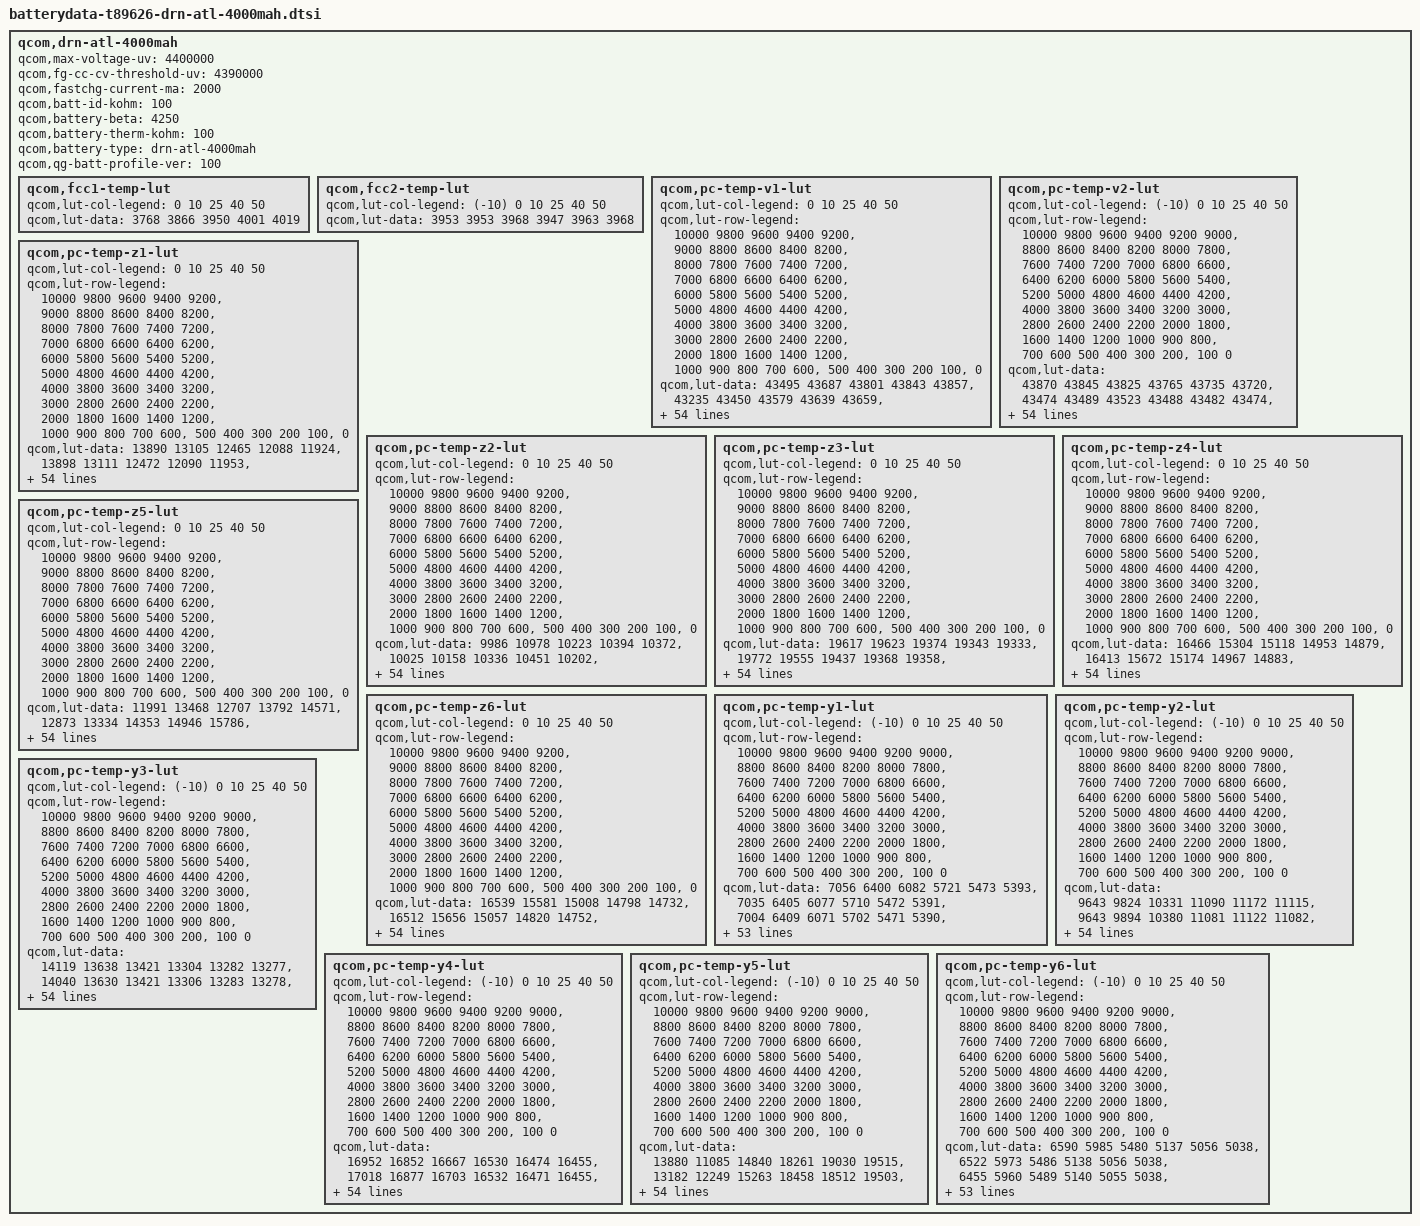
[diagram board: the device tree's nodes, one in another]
qcom,drn-atl-4000mah {
    /* 3818385_Wingtech_T89626AA1_DRN_4000mAH_FG_averaged_MasterSlave_Jan16th2019 */
    qcom,max-voltage-uv = <4400000>;
    qcom,fg-cc-cv-threshold-uv = <4390000>;
    qcom,fastchg-current-ma = <2000>;
    qcom,batt-id-kohm = <100>;
    qcom,battery-beta = <4250>;
    qcom,battery-therm-kohm = <100>;
    qcom,battery-type = "drn-atl-4000mah";
    qcom,qg-batt-profile-ver = <100>;

	qcom,fcc1-temp-lut {
		qcom,lut-col-legend = <0 10 25 40 50>;
		qcom,lut-data = <3768 3866 3950 4001 4019>;
	};

	qcom,fcc2-temp-lut {
		qcom,lut-col-legend = <(-10) 0 10 25 40 50>;
		qcom,lut-data = <3953 3953 3968 3947 3963 3968>;
	};

	qcom,pc-temp-v1-lut {
		qcom,lut-col-legend = <0 10 25 40 50>;
		qcom,lut-row-legend = <10000 9800 9600 9400 9200>,
			<9000 8800 8600 8400 8200>,
			<8000 7800 7600 7400 7200>,
			<7000 6800 6600 6400 6200>,
			<6000 5800 5600 5400 5200>,
			<5000 4800 4600 4400 4200>,
			<4000 3800 3600 3400 3200>,
			<3000 2800 2600 2400 2200>,
			<2000 1800 1600 1400 1200>,
			<1000 900 800 700 600>,
			<500 400 300 200 100>,
			<0>;
		qcom,lut-data = <43495 43687 43801 43843 43857>,
			<43235 43450 43579 43639 43659>,
			<42985 43208 43352 43423 43445>,
			<42747 42966 43120 43201 43225>,
			<42519 42728 42885 42972 42999>,
			<42296 42493 42651 42740 42769>,
			<42076 42263 42416 42508 42537>,
			<41860 42039 42184 42274 42304>,
			<41649 41819 41956 42043 42073>,
			<41442 41603 41731 41813 41845>,
			<41240 41389 41510 41587 41618>,
			<41050 41181 41293 41366 41396>,
			<40867 40991 41083 41149 41176>,
			<40667 40813 40886 40938 40963>,
			<40420 40617 40694 40732 40754>,
			<40169 40379 40500 40534 40553>,
			<39982 40144 40300 40343 40361>,
			<39840 39972 40109 40161 40177>,
			<39711 39838 39945 39986 39998>,
			<39580 39704 39791 39825 39833>,
			<39452 39561 39604 39647 39657>,
			<39328 39411 39354 39402 39429>,
			<39206 39233 39112 39136 39172>,
			<39087 39006 38929 38953 38981>,
			<38973 38803 38774 38823 38845>,
			<38862 38666 38663 38712 38729>,
			<38757 38558 38583 38609 38618>,
			<38653 38477 38515 38516 38517>,
			<38555 38416 38446 38428 38423>,
			<38473 38367 38380 38344 38333>,
			<38409 38324 38318 38268 38252>,
			<38355 38289 38257 38198 38179>,
			<38310 38256 38202 38136 38112>,
			<38272 38227 38151 38078 38049>,
			<38236 38201 38105 38026 37992>,
			<38198 38169 38060 37975 37934>,
			<38159 38134 38019 37925 37871>,
			<38112 38090 37974 37871 37805>,
			<38052 38019 37906 37800 37726>,
			<37979 37920 37809 37706 37634>,
			<37882 37813 37702 37601 37530>,
			<37752 37692 37585 37487 37416>,
			<37607 37553 37453 37358 37286>,
			<37448 37389 37293 37197 37129>,
			<37326 37254 37155 37062 36998>,
			<37232 37162 37064 36976 36916>,
			<37195 37133 37042 36952 36895>,
			<37165 37108 37024 36936 36877>,
			<37138 37080 37002 36912 36853>,
			<37066 37018 36935 36836 36769>,
			<36819 36754 36657 36539 36453>,
			<36368 36309 36215 36093 36007>,
			<35792 35734 35639 35514 35426>,
			<35015 34950 34856 34723 34632>,
			<33775 33715 33613 33488 33393>,
			<30000 30000 30000 30000 30000>;
	};

	qcom,pc-temp-v2-lut {
		qcom,lut-col-legend = <(-10) 0 10 25 40 50>;
		qcom,lut-row-legend = <10000 9800 9600 9400 9200 9000>,
			<8800 8600 8400 8200 8000 7800>,
			<7600 7400 7200 7000 6800 6600>,
			<6400 6200 6000 5800 5600 5400>,
			<5200 5000 4800 4600 4400 4200>,
			<4000 3800 3600 3400 3200 3000>,
			<2800 2600 2400 2200 2000 1800>,
			<1600 1400 1200 1000 900 800>,
			<700 600 500 400 300 200>,
			<100 0>;
		qcom,lut-data = <43870 43845 43825 43765 43735 43720>,
			<43474 43489 43523 43488 43482 43474>,
			<43114 43162 43237 43224 43236 43233>,
			<42791 42871 42969 42973 42996 42997>,
			<42496 42611 42719 42735 42764 42766>,
			<42243 42364 42476 42503 42533 42537>,
			<42049 42123 42229 42270 42301 42305>,
			<41877 41887 41987 42039 42070 42074>,
			<41657 41641 41759 41812 41843 41847>,
			<41357 41369 41545 41588 41617 41621>,
			<41101 41144 41334 41368 41395 41399>,
			<40971 41020 41117 41152 41179 41180>,
			<40874 40926 40902 40939 40966 40965>,
			<40684 40766 40703 40734 40760 40758>,
			<40218 40453 40524 40531 40557 40557>,
			<39763 40118 40334 40336 40361 40363>,
			<39540 39872 40107 40155 40174 40176>,
			<39381 39655 39857 39983 39996 39996>,
			<39218 39452 39625 39797 39816 39816>,
			<39043 39257 39408 39590 39638 39642>,
			<38876 39073 39205 39377 39453 39460>,
			<38719 38897 39016 39163 39232 39237>,
			<38570 38730 38842 38948 38992 38996>,
			<38446 38571 38686 38772 38805 38810>,
			<38343 38412 38546 38635 38665 38672>,
			<38255 38275 38418 38517 38546 38553>,
			<38179 38187 38291 38406 38437 38442>,
			<38113 38122 38171 38304 38338 38339>,
			<38052 38064 38077 38211 38247 38246>,
			<37995 38012 38002 38127 38162 38161>,
			<37940 37963 37941 38050 38085 38083>,
			<37885 37917 37893 37978 38013 38011>,
			<37831 37873 37855 37909 37948 37946>,
			<37774 37828 37816 37846 37878 37874>,
			<37715 37782 37778 37790 37800 37790>,
			<37654 37734 37737 37736 37718 37697>,
			<37590 37681 37691 37674 37627 37595>,
			<37523 37624 37641 37605 37529 37481>,
			<37454 37560 37579 37531 37438 37380>,
			<37387 37489 37499 37455 37361 37299>,
			<37319 37407 37404 37372 37284 37220>,
			<37253 37306 37301 37273 37187 37122>,
			<37187 37181 37185 37152 37070 37008>,
			<37116 37067 37046 37022 36943 36886>,
			<37036 36966 36912 36896 36836 36788>,
			<36936 36884 36831 36841 36794 36748>,
			<36883 36848 36804 36822 36780 36732>,
			<36812 36812 36773 36797 36759 36714>,
			<36723 36761 36728 36755 36721 36673>,
			<36574 36645 36628 36643 36586 36520>,
			<36322 36378 36358 36344 36230 36147>,
			<35914 35938 35895 35869 35724 35636>,
			<35323 35329 35262 35231 35069 34969>,
			<34461 34475 34383 34371 34169 34061>,
			<33112 33145 33039 32963 32816 32714>,
			<28445 28081 27842 28239 27825 27854>;
	};

	qcom,pc-temp-z1-lut {
		qcom,lut-col-legend = <0 10 25 40 50>;
		qcom,lut-row-legend = <10000 9800 9600 9400 9200>,
			<9000 8800 8600 8400 8200>,
			<8000 7800 7600 7400 7200>,
			<7000 6800 6600 6400 6200>,
			<6000 5800 5600 5400 5200>,
			<5000 4800 4600 4400 4200>,
			<4000 3800 3600 3400 3200>,
			<3000 2800 2600 2400 2200>,
			<2000 1800 1600 1400 1200>,
			<1000 900 800 700 600>,
			<500 400 300 200 100>,
			<0>;
		qcom,lut-data = <13890 13105 12465 12088 11924>,
			<13898 13111 12472 12090 11953>,
			<13902 13112 12474 12087 11956>,
			<13901 13106 12465 12083 11955>,
			<13899 13097 12449 12075 11952>,
			<13899 13082 12438 12067 11948>,
			<13893 13070 12430 12059 11946>,
			<13879 13058 12422 12053 11943>,
			<13874 13046 12412 12049 11943>,
			<13878 13045 12402 12047 11944>,
			<13879 13044 12397 12046 11945>,
			<13857 13040 12395 12046 11945>,
			<13808 13018 12392 12046 11945>,
			<13774 12977 12387 12046 11945>,
			<13747 12961 12382 12045 11944>,
			<13720 12964 12380 12044 11944>,
			<13709 12968 12380 12045 11945>,
			<13699 12970 12380 12046 11946>,
			<13692 12970 12384 12047 11947>,
			<13682 12971 12390 12047 11947>,
			<13663 12986 12392 12047 11948>,
			<13654 13009 12392 12047 11948>,
			<13667 13016 12391 12049 11948>,
			<13684 13017 12394 12051 11949>,
			<13694 13016 12402 12053 11951>,
			<13706 13012 12407 12055 11953>,
			<13714 13007 12411 12059 11956>,
			<13706 13005 12415 12063 11960>,
			<13690 13006 12421 12067 11964>,
			<13684 13010 12431 12072 11968>,
			<13707 13018 12437 12076 11972>,
			<13734 13039 12439 12082 11976>,
			<13736 13051 12441 12087 11980>,
			<13725 13053 12446 12092 11983>,
			<13717 13053 12458 12097 11987>,
			<13726 13059 12465 12102 11991>,
			<13744 13076 12467 12105 11994>,
			<13753 13088 12470 12109 11997>,
			<13749 13085 12476 12114 12000>,
			<13745 13080 12488 12120 12005>,
			<13765 13082 12497 12126 12009>,
			<13827 13109 12501 12131 12013>,
			<13838 13126 12505 12136 12016>,
			<13817 13124 12511 12142 12019>,
			<13817 13120 12525 12150 12024>,
			<13790 13112 12541 12154 12027>,
			<13806 13122 12531 12156 12027>,
			<13811 13106 12536 12161 12030>,
			<13812 13120 12532 12166 12035>,
			<13836 13143 12546 12170 12039>,
			<13842 13126 12546 12181 12047>,
			<13816 13166 12547 12186 12055>,
			<13829 13180 12568 12197 12065>,
			<13860 13219 12612 12217 12078>,
			<13860 13219 12612 12217 12078>,
			<13860 13219 12612 12217 12078>;
	};

	qcom,pc-temp-z2-lut {
		qcom,lut-col-legend = <0 10 25 40 50>;
		qcom,lut-row-legend = <10000 9800 9600 9400 9200>,
			<9000 8800 8600 8400 8200>,
			<8000 7800 7600 7400 7200>,
			<7000 6800 6600 6400 6200>,
			<6000 5800 5600 5400 5200>,
			<5000 4800 4600 4400 4200>,
			<4000 3800 3600 3400 3200>,
			<3000 2800 2600 2400 2200>,
			<2000 1800 1600 1400 1200>,
			<1000 900 800 700 600>,
			<500 400 300 200 100>,
			<0>;
		qcom,lut-data = <9986 10978 10223 10394 10372>,
			<10025 10158 10336 10451 10202>,
			<10062 10152 10386 10493 10362>,
			<10100 10150 10377 10498 10446>,
			<10141 10141 10355 10480 10462>,
			<10159 10116 10332 10454 10466>,
			<10159 10093 10302 10420 10455>,
			<10158 10079 10277 10380 10425>,
			<10156 10067 10255 10358 10390>,
			<10150 10056 10239 10345 10337>,
			<10143 10045 10236 10336 10283>,
			<10130 10038 10244 10327 10252>,
			<10110 10053 10255 10313 10230>,
			<10086 10105 10404 10301 10233>,
			<10048 10131 10613 10289 10244>,
			<10012 10103 10655 10281 10257>,
			<10005 10068 10650 10282 10271>,
			<10007 10072 10636 10293 10285>,
			<10008 10102 10531 10299 10300>,
			<10005 10128 10376 10303 10323>,
			<9997 10143 10346 10311 10343>,
			<9990 10154 10375 10346 10347>,
			<9979 10163 10396 10391 10342>,
			<9968 10172 10386 10388 10340>,
			<9966 10176 10360 10335 10358>,
			<9968 10175 10345 10306 10376>,
			<9970 10172 10346 10347 10390>,
			<9975 10172 10354 10424 10410>,
			<9984 10183 10369 10459 10402>,
			<9993 10196 10394 10474 10337>,
			<10001 10200 10405 10475 10275>,
			<10009 10202 10409 10456 10250>,
			<10017 10204 10412 10428 10231>,
			<10025 10209 10415 10421 10230>,
			<10033 10215 10418 10419 10260>,
			<10045 10220 10422 10423 10300>,
			<10058 10226 10430 10445 10343>,
			<10073 10233 10441 10480 10390>,
			<10090 10244 10456 10510 10427>,
			<10108 10257 10481 10550 10459>,
			<10119 10266 10500 10571 10478>,
			<10128 10270 10514 10556 10476>,
			<10147 10275 10520 10534 10470>,
			<10182 10283 10508 10509 10457>,
			<10280 10408 10544 10508 10462>,
			<10163 10447 10566 10527 10462>,
			<10620 10489 10541 10502 10470>,
			<12381 10555 10535 10524 10463>,
			<14367 10597 10521 10524 10500>,
			<15164 10649 10579 10627 10671>,
			<11677 10631 10687 10622 10375>,
			<10005 10560 10698 10469 10270>,
			<9961 10482 10664 10416 10218>,
			<9793 10361 10621 10333 10175>,
			<9793 10361 10621 10333 10175>,
			<9793 10361 10621 10333 10175>;
	};

	qcom,pc-temp-z3-lut {
		qcom,lut-col-legend = <0 10 25 40 50>;
		qcom,lut-row-legend = <10000 9800 9600 9400 9200>,
			<9000 8800 8600 8400 8200>,
			<8000 7800 7600 7400 7200>,
			<7000 6800 6600 6400 6200>,
			<6000 5800 5600 5400 5200>,
			<5000 4800 4600 4400 4200>,
			<4000 3800 3600 3400 3200>,
			<3000 2800 2600 2400 2200>,
			<2000 1800 1600 1400 1200>,
			<1000 900 800 700 600>,
			<500 400 300 200 100>,
			<0>;
		qcom,lut-data = <19617 19623 19374 19343 19333>,
			<19772 19555 19437 19368 19358>,
			<19859 19599 19475 19395 19372>,
			<19853 19661 19495 19409 19381>,
			<19818 19684 19507 19417 19391>,
			<19784 19695 19511 19422 19399>,
			<19749 19699 19513 19423 19402>,
			<19716 19694 19513 19423 19402>,
			<19707 19682 19511 19423 19402>,
			<19706 19676 19506 19418 19396>,
			<19706 19675 19499 19412 19387>,
			<19706 19673 19486 19404 19381>,
			<19705 19665 19475 19394 19375>,
			<19705 19649 19475 19389 19371>,
			<19740 19638 19478 19386 19367>,
			<19788 19629 19476 19382 19362>,
			<19794 19617 19469 19376 19357>,
			<19768 19600 19460 19370 19352>,
			<19744 19573 19449 19366 19349>,
			<19744 19559 19437 19364 19346>,
			<19751 19561 19436 19363 19344>,
			<19758 19568 19449 19369 19346>,
			<19771 19576 19460 19379 19349>,
			<19785 19593 19458 19379 19348>,
			<19789 19604 19451 19367 19338>,
			<19791 19603 19445 19358 19330>,
			<19791 19600 19438 19358 19334>,
			<19791 19597 19434 19363 19346>,
			<19790 19594 19435 19369 19355>,
			<19789 19590 19439 19383 19367>,
			<19781 19586 19444 19394 19375>,
			<19768 19582 19453 19397 19374>,
			<19755 19577 19459 19397 19370>,
			<19740 19570 19459 19394 19366>,
			<19725 19563 19455 19386 19358>,
			<19713 19558 19450 19379 19352>,
			<19703 19553 19446 19375 19352>,
			<19691 19550 19441 19371 19351>,
			<19675 19548 19437 19368 19350>,
			<19661 19547 19434 19366 19348>,
			<19653 19544 19432 19364 19346>,
			<19648 19539 19429 19362 19347>,
			<19642 19532 19427 19360 19348>,
			<19633 19524 19420 19359 19348>,
			<19403 19481 19406 19353 19343>,
			<19279 19454 19401 19349 19338>,
			<19283 19432 19392 19348 19329>,
			<19283 19410 19377 19340 19328>,
			<19258 19398 19366 19339 19323>,
			<19257 19384 19360 19330 19312>,
			<19261 19399 19355 19333 19347>,
			<19271 19360 19341 19346 19350>,
			<19313 19352 19340 19347 19351>,
			<19315 19346 19332 19353 19354>,
			<19315 19346 19332 19353 19354>,
			<19315 19346 19332 19353 19354>;
	};

	qcom,pc-temp-z4-lut {
		qcom,lut-col-legend = <0 10 25 40 50>;
		qcom,lut-row-legend = <10000 9800 9600 9400 9200>,
			<9000 8800 8600 8400 8200>,
			<8000 7800 7600 7400 7200>,
			<7000 6800 6600 6400 6200>,
			<6000 5800 5600 5400 5200>,
			<5000 4800 4600 4400 4200>,
			<4000 3800 3600 3400 3200>,
			<3000 2800 2600 2400 2200>,
			<2000 1800 1600 1400 1200>,
			<1000 900 800 700 600>,
			<500 400 300 200 100>,
			<0>;
		qcom,lut-data = <16466 15304 15118 14953 14879>,
			<16413 15672 15174 14967 14883>,
			<16332 15578 15187 14960 14885>,
			<16213 15419 15131 14945 14882>,
			<16044 15293 15034 14905 14858>,
			<15891 15179 14967 14864 14825>,
			<15775 15086 14915 14834 14799>,
			<15672 15020 14871 14808 14777>,
			<15579 14966 14835 14783 14759>,
			<15494 14921 14803 14759 14743>,
			<15415 14882 14781 14743 14732>,
			<15340 14847 14765 14735 14725>,
			<15270 14808 14749 14729 14718>,
			<15205 14766 14721 14721 14711>,
			<15139 14747 14693 14711 14702>,
			<15078 14753 14686 14702 14695>,
			<15038 14763 14685 14695 14688>,
			<15012 14761 14684 14690 14681>,
			<14986 14754 14683 14685 14676>,
			<14948 14745 14685 14679 14673>,
			<14901 14733 14695 14677 14671>,
			<14863 14722 14746 14721 14705>,
			<14831 14726 14804 14799 14784>,
			<14805 14779 14839 14828 14817>,
			<14792 14828 14868 14839 14826>,
			<14784 14843 14874 14843 14829>,
			<14780 14852 14861 14833 14819>,
			<14781 14853 14840 14812 14791>,
			<14784 14839 14820 14788 14764>,
			<14786 14819 14797 14757 14736>,
			<14784 14802 14775 14731 14712>,
			<14782 14785 14751 14712 14698>,
			<14779 14770 14733 14698 14687>,
			<14775 14755 14724 14695 14684>,
			<14771 14741 14718 14695 14684>,
			<14765 14729 14715 14695 14684>,
			<14757 14718 14714 14697 14687>,
			<14752 14712 14713 14701 14693>,
			<14748 14714 14716 14707 14699>,
			<14745 14717 14726 14718 14708>,
			<14743 14718 14731 14724 14713>,
			<14742 14715 14721 14716 14706>,
			<14736 14712 14712 14708 14697>,
			<14724 14711 14711 14711 14701>,
			<14874 14699 14693 14701 14694>,
			<14994 14700 14675 14679 14675>,
			<14984 14713 14668 14667 14670>,
			<14976 14728 14670 14653 14650>,
			<14992 14735 14669 14638 14636>,
			<14983 14745 14674 14653 14650>,
			<14984 14741 14707 14681 14651>,
			<14999 14801 14730 14672 14651>,
			<14976 14821 14734 14673 14654>,
			<14991 14839 14749 14671 14653>,
			<14991 14839 14749 14671 14653>,
			<14991 14839 14749 14671 14653>;
	};

	qcom,pc-temp-z5-lut {
		qcom,lut-col-legend = <0 10 25 40 50>;
		qcom,lut-row-legend = <10000 9800 9600 9400 9200>,
			<9000 8800 8600 8400 8200>,
			<8000 7800 7600 7400 7200>,
			<7000 6800 6600 6400 6200>,
			<6000 5800 5600 5400 5200>,
			<5000 4800 4600 4400 4200>,
			<4000 3800 3600 3400 3200>,
			<3000 2800 2600 2400 2200>,
			<2000 1800 1600 1400 1200>,
			<1000 900 800 700 600>,
			<500 400 300 200 100>,
			<0>;
		qcom,lut-data = <11991 13468 12707 13792 14571>,
			<12873 13334 14353 14946 15786>,
			<13396 13888 15503 16213 16665>,
			<13424 14831 16164 16884 17319>,
			<13398 15555 16671 17226 17967>,
			<13386 16206 17239 17543 18613>,
			<13392 16729 17828 17925 19152>,
			<13406 17034 18428 18331 19645>,
			<13458 17283 19168 18833 20042>,
			<13605 17714 19960 19582 20212>,
			<13747 18719 20403 20033 20139>,
			<13788 19795 20657 19847 20017>,
			<13796 20642 20963 19506 20135>,
			<13866 21601 24059 19579 20376>,
			<14755 22125 28256 20465 20922>,
			<15913 23083 28845 21145 21337>,
			<16091 24052 28059 21236 21442>,
			<15693 23691 27362 21282 21880>,
			<15365 21871 26872 21513 22440>,
			<15674 20757 26764 22620 23599>,
			<16713 22655 29176 24258 24881>,
			<17959 27078 41207 28694 26151>,
			<19828 33497 50895 33800 27170>,
			<22221 46082 47651 33277 26202>,
			<24630 54930 38554 25960 21272>,
			<27220 53025 31937 20267 17156>,
			<29969 47563 27294 18922 16571>,
			<33446 43319 24367 18141 16711>,
			<37140 40429 23766 18301 17419>,
			<38387 38077 23668 20231 19181>,
			<37552 36306 24131 22739 21309>,
			<36027 34883 27543 26055 23539>,
			<34063 33791 32201 29773 25830>,
			<30999 32800 35838 31642 27160>,
			<28493 32080 39316 32817 27978>,
			<27382 32034 40673 33303 28497>,
			<26603 32498 40639 32658 28874>,
			<25779 33229 40327 31158 29185>,
			<24595 34984 39023 29272 28761>,
			<23667 37403 35514 26393 25267>,
			<23687 37804 32847 24136 22436>,
			<24338 34795 31813 23143 22305>,
			<25612 32372 30644 22367 22342>,
			<27598 30930 27451 21379 21616>,
			<15578 26808 27864 21270 20863>,
			<11370 21931 28900 21718 20796>,
			<11409 18245 25503 22576 19118>,
			<11403 15889 22025 21937 21237>,
			<11144 15182 18784 25009 23779>,
			<11173 14809 18156 19576 17398>,
			<11253 15722 16182 16083 21431>,
			<11297 13230 14126 17230 20727>,
			<11631 12714 13797 16766 19688>,
			<11513 12350 13126 17045 19104>,
			<11513 12350 13126 17045 19104>,
			<11513 12350 13126 17045 19104>;
	};

	qcom,pc-temp-z6-lut {
		qcom,lut-col-legend = <0 10 25 40 50>;
		qcom,lut-row-legend = <10000 9800 9600 9400 9200>,
			<9000 8800 8600 8400 8200>,
			<8000 7800 7600 7400 7200>,
			<7000 6800 6600 6400 6200>,
			<6000 5800 5600 5400 5200>,
			<5000 4800 4600 4400 4200>,
			<4000 3800 3600 3400 3200>,
			<3000 2800 2600 2400 2200>,
			<2000 1800 1600 1400 1200>,
			<1000 900 800 700 600>,
			<500 400 300 200 100>,
			<0>;
		qcom,lut-data = <16539 15581 15008 14798 14732>,
			<16512 15656 15057 14820 14752>,
			<16460 15613 15073 14828 14760>,
			<16375 15536 15051 14827 14762>,
			<16238 15469 15009 14812 14755>,
			<16113 15401 14978 14796 14746>,
			<16015 15341 14951 14783 14737>,
			<15929 15293 14926 14771 14729>,
			<15861 15251 14905 14759 14720>,
			<15807 15219 14886 14746 14710>,
			<15758 15194 14869 14735 14700>,
			<15707 15170 14855 14726 14693>,
			<15658 15139 14842 14719 14687>,
			<15620 15103 14830 14712 14681>,
			<15595 15083 14819 14705 14675>,
			<15574 15076 14812 14699 14669>,
			<15549 15070 14807 14693 14663>,
			<15522 15060 14803 14687 14657>,
			<15496 15045 14798 14683 14653>,
			<15473 15037 14793 14679 14650>,
			<15452 15037 14795 14677 14648>,
			<15442 15038 14824 14701 14665>,
			<15439 15044 14856 14740 14700>,
			<15437 15077 14870 14749 14711>,
			<15437 15106 14880 14749 14711>,
			<15438 15113 14882 14748 14711>,
			<15439 15116 14874 14745 14708>,
			<15440 15117 14864 14739 14703>,
			<15441 15110 14857 14733 14698>,
			<15441 15101 14851 14728 14693>,
			<15438 15094 14846 14723 14688>,
			<15434 15088 14842 14718 14682>,
			<15428 15081 14839 14713 14677>,
			<15421 15073 14836 14709 14672>,
			<15415 15065 14833 14706 14668>,
			<15412 15061 14831 14704 14666>,
			<15409 15059 14830 14703 14666>,
			<15406 15058 14829 14703 14669>,
			<15401 15061 14830 14704 14671>,
			<15397 15067 14836 14708 14674>,
			<15398 15070 14839 14711 14676>,
			<15406 15071 14836 14708 14674>,
			<15408 15072 14833 14704 14672>,
			<15409 15076 14833 14706 14673>,
			<15367 15062 14824 14700 14669>,
			<15364 15049 14817 14689 14658>,
			<15361 15047 14810 14684 14651>,
			<15359 15042 14804 14675 14643>,
			<15360 15044 14800 14668 14634>,
			<15362 15043 14802 14671 14635>,
			<15371 15056 14818 14687 14656>,
			<15395 15073 14825 14692 14661>,
			<15418 15087 14831 14697 14664>,
			<15444 15106 14843 14703 14669>,
			<15444 15106 14843 14703 14669>,
			<15444 15106 14843 14703 14669>;
	};

	qcom,pc-temp-y1-lut {
		qcom,lut-col-legend = <(-10) 0 10 25 40 50>;
		qcom,lut-row-legend = <10000 9800 9600 9400 9200 9000>,
			<8800 8600 8400 8200 8000 7800>,
			<7600 7400 7200 7000 6800 6600>,
			<6400 6200 6000 5800 5600 5400>,
			<5200 5000 4800 4600 4400 4200>,
			<4000 3800 3600 3400 3200 3000>,
			<2800 2600 2400 2200 2000 1800>,
			<1600 1400 1200 1000 900 800>,
			<700 600 500 400 300 200>,
			<100 0>;
		qcom,lut-data = <7056 6400 6082 5721 5473 5393>,
			<7035 6405 6077 5710 5472 5391>,
			<7004 6409 6071 5702 5471 5390>,
			<6969 6411 6065 5697 5469 5388>,
			<6940 6413 6058 5694 5467 5386>,
			<6924 6412 6053 5694 5465 5384>,
			<6920 6409 6047 5696 5462 5382>,
			<6918 6404 6042 5700 5459 5380>,
			<6920 6403 6041 5701 5457 5378>,
			<6938 6408 6039 5694 5454 5376>,
			<6954 6412 6038 5689 5452 5374>,
			<6961 6412 6042 5688 5451 5373>,
			<6972 6412 6050 5688 5450 5372>,
			<6974 6409 6051 5687 5449 5371>,
			<6967 6391 6046 5685 5446 5370>,
			<6959 6376 6044 5683 5444 5369>,
			<6948 6388 6049 5683 5444 5369>,
			<6928 6417 6058 5684 5444 5368>,
			<6923 6428 6059 5685 5444 5368>,
			<6932 6425 6048 5688 5443 5368>,
			<6941 6421 6040 5690 5442 5367>,
			<6936 6418 6043 5690 5442 5368>,
			<6923 6415 6050 5687 5443 5368>,
			<6917 6415 6051 5686 5444 5368>,
			<6936 6422 6047 5688 5446 5369>,
			<6955 6428 6044 5691 5447 5370>,
			<6949 6424 6046 5695 5449 5371>,
			<6933 6415 6050 5702 5451 5373>,
			<6918 6406 6050 5706 5453 5375>,
			<6903 6400 6049 5707 5457 5378>,
			<6891 6395 6048 5709 5461 5380>,
			<6896 6392 6051 5711 5465 5383>,
			<6917 6388 6059 5714 5469 5385>,
			<6926 6386 6062 5717 5472 5388>,
			<6923 6389 6059 5727 5475 5390>,
			<6918 6393 6056 5736 5478 5392>,
			<6914 6392 6054 5737 5480 5394>,
			<6915 6384 6052 5735 5481 5395>,
			<6913 6373 6052 5734 5483 5397>,
			<6896 6358 6050 5740 5486 5399>,
			<6873 6345 6048 5749 5490 5402>,
			<6858 6348 6048 5754 5494 5404>,
			<6847 6366 6050 5757 5498 5407>,
			<6846 6371 6047 5765 5504 5410>,
			<6852 6372 6045 5777 5511 5415>,
			<6866 6383 6050 5781 5517 5420>,
			<6913 6379 6065 5788 5518 5419>,
			<6926 6391 6063 5781 5522 5419>,
			<6952 6391 6061 5774 5520 5420>,
			<6915 6416 6053 5796 5519 5420>,
			<6933 6415 6058 5799 5522 5424>,
			<6935 6406 6064 5809 5536 5431>,
			<6948 6409 6079 5818 5547 5439>,
			<6994 6427 6086 5829 5560 5449>,
			<6994 6427 6086 5829 5560 5449>,
			<6994 6427 6086 5829 5560 5449>;
	};

	qcom,pc-temp-y2-lut {
		qcom,lut-col-legend = <(-10) 0 10 25 40 50>;
		qcom,lut-row-legend = <10000 9800 9600 9400 9200 9000>,
			<8800 8600 8400 8200 8000 7800>,
			<7600 7400 7200 7000 6800 6600>,
			<6400 6200 6000 5800 5600 5400>,
			<5200 5000 4800 4600 4400 4200>,
			<4000 3800 3600 3400 3200 3000>,
			<2800 2600 2400 2200 2000 1800>,
			<1600 1400 1200 1000 900 800>,
			<700 600 500 400 300 200>,
			<100 0>;
		qcom,lut-data = <9643 9824 10331 11090 11172 11115>,
			<9643 9894 10380 11081 11122 11082>,
			<9643 9960 10427 11064 11069 11048>,
			<9717 10023 10471 11043 11017 11014>,
			<9793 10078 10510 11021 10974 10983>,
			<9859 10124 10541 11003 10944 10957>,
			<10006 10155 10567 10983 10926 10935>,
			<10213 10182 10588 10962 10913 10914>,
			<10274 10245 10596 10953 10907 10898>,
			<10176 10415 10595 10947 10903 10883>,
			<10095 10537 10596 10945 10901 10875>,
			<10204 10517 10664 10948 10935 10886>,
			<10405 10472 10789 10960 11007 10914>,
			<10409 10469 10841 10980 11050 10943>,
			<10030 10564 10857 11034 11071 10997>,
			<9703 10669 10871 11089 11095 11055>,
			<9687 10718 10894 11113 11149 11096>,
			<9685 10753 10921 11130 11231 11136>,
			<9683 10785 10928 11148 11316 11206>,
			<9680 10819 10923 11172 11421 11390>,
			<9678 10840 10920 11190 11489 11526>,
			<9677 10829 10929 11183 11404 11426>,
			<9675 10780 10947 11160 11205 11200>,
			<9674 10680 10956 11151 11135 11125>,
			<9673 10212 10960 11165 11140 11128>,
			<9672 9753 10963 11186 11150 11135>,
			<9670 9708 10956 11199 11191 11147>,
			<9669 9703 10940 11211 11272 11169>,
			<9668 9699 10930 11226 11317 11196>,
			<9668 9695 10930 11253 11340 11238>,
			<9667 9691 10929 11280 11361 11278>,
			<9666 9686 10919 11282 11388 11310>,
			<9665 9681 10896 11276 11431 11340>,
			<9664 9677 10870 11269 11444 11349>,
			<9663 9674 10841 11261 11416 11331>,
			<9663 9671 10800 11250 11373 11303>,
			<9662 9669 10662 11234 11332 11273>,
			<9662 9667 10416 11202 11291 11235>,
			<9662 9665 10267 11167 11260 11202>,
			<9661 9664 10025 11139 11234 11171>,
			<9661 9663 9758 11109 11209 11149>,
			<9661 9662 9696 11070 11187 11144>,
			<9660 9661 9680 11016 11167 11145>,
			<9660 9660 9673 10943 11145 11109>,
			<9659 9660 9669 10844 11112 11024>,
			<9659 9659 9667 10808 11049 10958>,
			<9659 9659 9667 10844 11083 10951>,
			<9658 9659 9665 10852 11131 10985>,
			<9658 9658 9663 10841 11128 11036>,
			<9658 9658 9662 10833 11108 11002>,
			<9657 9658 9661 10765 11043 10887>,
			<9657 9657 9659 10712 10982 10822>,
			<9656 9656 9658 10618 10944 10757>,
			<9653 9656 9656 10551 10872 10720>,
			<9653 9656 9656 10551 10872 10720>,
			<9653 9656 9656 10551 10872 10720>;
	};

	qcom,pc-temp-y3-lut {
		qcom,lut-col-legend = <(-10) 0 10 25 40 50>;
		qcom,lut-row-legend = <10000 9800 9600 9400 9200 9000>,
			<8800 8600 8400 8200 8000 7800>,
			<7600 7400 7200 7000 6800 6600>,
			<6400 6200 6000 5800 5600 5400>,
			<5200 5000 4800 4600 4400 4200>,
			<4000 3800 3600 3400 3200 3000>,
			<2800 2600 2400 2200 2000 1800>,
			<1600 1400 1200 1000 900 800>,
			<700 600 500 400 300 200>,
			<100 0>;
		qcom,lut-data = <14119 13638 13421 13304 13282 13277>,
			<14040 13630 13421 13306 13283 13278>,
			<13947 13620 13421 13309 13284 13279>,
			<13855 13610 13421 13311 13284 13280>,
			<13775 13600 13421 13313 13285 13281>,
			<13720 13589 13420 13315 13286 13282>,
			<13691 13577 13420 13316 13286 13283>,
			<13667 13565 13420 13318 13287 13284>,
			<13637 13548 13421 13320 13288 13285>,
			<13584 13520 13429 13321 13288 13286>,
			<13539 13492 13435 13322 13289 13287>,
			<13517 13467 13417 13322 13291 13287>,
			<13500 13445 13385 13322 13295 13287>,
			<13495 13440 13378 13321 13296 13288>,
			<13496 13447 13383 13320 13295 13291>,
			<13497 13452 13387 13318 13295 13293>,
			<13493 13445 13385 13316 13294 13293>,
			<13487 13425 13378 13314 13295 13292>,
			<13483 13410 13371 13313 13295 13292>,
			<13479 13399 13364 13312 13295 13291>,
			<13476 13390 13357 13311 13295 13290>,
			<13471 13384 13352 13309 13292 13286>,
			<13465 13380 13348 13304 13287 13280>,
			<13459 13371 13344 13302 13284 13278>,
			<13452 13336 13339 13302 13283 13279>,
			<13447 13302 13335 13302 13282 13279>,
			<13450 13301 13332 13301 13282 13279>,
			<13462 13307 13330 13300 13283 13278>,
			<13478 13314 13328 13300 13283 13277>,
			<13499 13320 13324 13300 13283 13277>,
			<13523 13327 13322 13300 13283 13277>,
			<13548 13344 13323 13300 13283 13277>,
			<13573 13375 13326 13299 13284 13278>,
			<13600 13403 13329 13299 13285 13278>,
			<13632 13422 13331 13300 13285 13279>,
			<13666 13439 13333 13301 13284 13279>,
			<13699 13461 13335 13301 13283 13279>,
			<13731 13488 13340 13300 13282 13277>,
			<13763 13517 13345 13299 13281 13277>,
			<13797 13547 13354 13299 13282 13277>,
			<13831 13578 13365 13300 13283 13278>,
			<13867 13609 13376 13301 13282 13278>,
			<13904 13639 13389 13302 13282 13279>,
			<13948 13672 13406 13304 13282 13279>,
			<14000 13707 13435 13306 13282 13280>,
			<14041 13739 13461 13311 13286 13283>,
			<14014 13729 13460 13312 13290 13285>,
			<14055 13760 13492 13314 13294 13290>,
			<14117 13800 13530 13321 13298 13292>,
			<14176 13834 13566 13325 13297 13289>,
			<14244 13873 13601 13324 13292 13286>,
			<14337 13928 13660 13329 13295 13287>,
			<14452 14017 13743 13335 13300 13290>,
			<14827 14127 13838 13350 13306 13297>,
			<14827 14127 13838 13350 13306 13297>,
			<14827 14127 13838 13350 13306 13297>;
	};

	qcom,pc-temp-y4-lut {
		qcom,lut-col-legend = <(-10) 0 10 25 40 50>;
		qcom,lut-row-legend = <10000 9800 9600 9400 9200 9000>,
			<8800 8600 8400 8200 8000 7800>,
			<7600 7400 7200 7000 6800 6600>,
			<6400 6200 6000 5800 5600 5400>,
			<5200 5000 4800 4600 4400 4200>,
			<4000 3800 3600 3400 3200 3000>,
			<2800 2600 2400 2200 2000 1800>,
			<1600 1400 1200 1000 900 800>,
			<700 600 500 400 300 200>,
			<100 0>;
		qcom,lut-data = <16952 16852 16667 16530 16474 16455>,
			<17018 16877 16703 16532 16471 16455>,
			<17064 16916 16750 16536 16470 16455>,
			<17092 16957 16798 16539 16470 16454>,
			<17106 16990 16835 16543 16471 16454>,
			<17109 17005 16850 16545 16472 16454>,
			<17090 17002 16846 16545 16474 16455>,
			<17060 16997 16837 16546 16478 16457>,
			<17063 16997 16830 16548 16482 16460>,
			<17139 17007 16823 16551 16487 16463>,
			<17220 17024 16820 16556 16492 16467>,
			<17273 17114 16864 16562 16495 16472>,
			<17321 17266 16944 16571 16497 16479>,
			<17308 17290 16964 16583 16501 16484>,
			<17082 17104 16959 16605 16512 16488>,
			<16884 16913 16950 16629 16526 16493>,
			<16874 16854 16911 16654 16542 16503>,
			<16872 16819 16835 16678 16560 16518>,
			<16867 16788 16777 16684 16574 16534>,
			<16840 16763 16736 16660 16585 16554>,
			<16807 16738 16700 16622 16591 16567>,
			<16782 16698 16665 16579 16563 16542>,
			<16759 16652 16634 16527 16496 16486>,
			<16753 16638 16611 16504 16470 16463>,
			<16759 16658 16596 16499 16467 16459>,
			<16766 16680 16580 16497 16466 16457>,
			<16766 16681 16555 16498 16468 16460>,
			<16766 16678 16525 16502 16475 16468>,
			<16766 16677 16515 16507 16484 16476>,
			<16759 16680 16516 16513 16495 16486>,
			<16751 16683 16518 16518 16506 16497>,
			<16749 16679 16521 16521 16516 16508>,
			<16749 16666 16528 16523 16525 16520>,
			<16748 16660 16537 16523 16528 16524>,
			<16748 16667 16550 16522 16523 16518>,
			<16749 16678 16566 16520 16513 16507>,
			<16750 16685 16584 16517 16499 16492>,
			<16752 16692 16605 16508 16479 16472>,
			<16757 16695 16621 16504 16470 16465>,
			<16765 16695 16635 16508 16473 16468>,
			<16779 16695 16646 16516 16477 16471>,
			<16794 16688 16649 16523 16479 16472>,
			<16817 16666 16651 16531 16480 16470>,
			<16843 16658 16644 16532 16474 16461>,
			<16867 16657 16633 16528 16466 16451>,
			<16867 16676 16634 16545 16479 16464>,
			<16808 16676 16636 16540 16484 16480>,
			<16809 16692 16657 16551 16500 16502>,
			<16821 16718 16687 16576 16527 16525>,
			<16823 16736 16712 16588 16519 16507>,
			<16808 16723 16699 16572 16477 16461>,
			<16791 16707 16682 16568 16476 16462>,
			<16800 16714 16690 16586 16490 16470>,
			<16938 16749 16729 16639 16536 16511>,
			<16938 16749 16729 16639 16536 16511>,
			<16938 16749 16729 16639 16536 16511>;
	};

	qcom,pc-temp-y5-lut {
		qcom,lut-col-legend = <(-10) 0 10 25 40 50>;
		qcom,lut-row-legend = <10000 9800 9600 9400 9200 9000>,
			<8800 8600 8400 8200 8000 7800>,
			<7600 7400 7200 7000 6800 6600>,
			<6400 6200 6000 5800 5600 5400>,
			<5200 5000 4800 4600 4400 4200>,
			<4000 3800 3600 3400 3200 3000>,
			<2800 2600 2400 2200 2000 1800>,
			<1600 1400 1200 1000 900 800>,
			<700 600 500 400 300 200>,
			<100 0>;
		qcom,lut-data = <13880 11085 14840 18261 19030 19515>,
			<13182 12249 15263 18458 18512 19503>,
			<13027 13493 15679 18636 18010 19409>,
			<13319 14687 16070 18770 17526 19245>,
			<13963 15701 16416 18835 17063 19026>,
			<14863 16402 16699 18805 16622 18764>,
			<17375 16863 16887 18689 16198 18446>,
			<20746 17186 17058 18516 15797 18070>,
			<20988 17037 17473 18261 15407 17671>,
			<17001 15518 18555 17805 14965 17237>,
			<13875 14328 19272 17257 14717 16772>,
			<16023 14903 17686 16641 15013 16160>,
			<20359 16526 14818 15955 15573 15555>,
			<21198 18626 14544 15456 15637 15463>,
			<17308 22349 17999 14954 14901 15813>,
			<13943 25005 21051 14643 14220 16090>,
			<13949 24270 21658 14823 14082 15694>,
			<14226 22438 21996 15482 14068 14937>,
			<14353 21849 22286 16532 14429 14879>,
			<14405 22198 22527 19461 16999 16178>,
			<14424 22722 22775 22078 19651 17635>,
			<14202 23333 23157 22371 20658 18497>,
			<13599 24058 23602 22383 21321 19215>,
			<13068 23978 23819 22421 21395 19526>,
			<12583 18493 23801 22550 20199 19596>,
			<12256 12751 23722 22659 18879 19519>,
			<12231 12291 23297 22375 18526 18635>,
			<12232 12327 22475 21420 18336 16858>,
			<12243 12343 21732 20958 18137 16088>,
			<12436 12301 19469 21288 17778 15910>,
			<12723 12258 17339 21801 17541 15829>,
			<12931 12460 17444 22167 17917 15941>,
			<13109 13188 18102 22490 18967 16347>,
			<13223 13700 18360 22815 19836 16968>,
			<13326 13887 18382 23240 20524 18502>,
			<13411 14018 18398 23618 20976 19824>,
			<13397 14121 18235 23423 20736 19749>,
			<13265 14320 17875 22040 20018 19208>,
			<13122 14540 17573 20550 19763 18693>,
			<12972 14783 16494 19413 19367 18126>,
			<12834 14991 15186 18392 18763 17686>,
			<12807 14911 14796 17711 18328 17710>,
			<12864 14425 14727 17230 17716 18046>,
			<12976 14052 14421 17382 17641 18741>,
			<13298 13738 14185 17851 17135 19231>,
			<13582 13366 14165 17133 16293 17208>,
			<14007 13396 14083 17399 17249 16717>,
			<14118 13718 14112 16859 17672 17471>,
			<14452 14307 14205 17007 18415 17605>,
			<14466 14437 14439 17522 18441 17143>,
			<14521 14270 14455 18616 18883 18473>,
			<14109 14101 14615 19972 21076 19030>,
			<13686 14075 14452 19383 23767 20501>,
			<12899 14426 14449 19785 25506 25729>,
			<12899 14426 14449 19785 25506 25729>,
			<12899 14426 14449 19785 25506 25729>;
	};

	qcom,pc-temp-y6-lut {
		qcom,lut-col-legend = <(-10) 0 10 25 40 50>;
		qcom,lut-row-legend = <10000 9800 9600 9400 9200 9000>,
			<8800 8600 8400 8200 8000 7800>,
			<7600 7400 7200 7000 6800 6600>,
			<6400 6200 6000 5800 5600 5400>,
			<5200 5000 4800 4600 4400 4200>,
			<4000 3800 3600 3400 3200 3000>,
			<2800 2600 2400 2200 2000 1800>,
			<1600 1400 1200 1000 900 800>,
			<700 600 500 400 300 200>,
			<100 0>;
		qcom,lut-data = <6590 5985 5480 5137 5056 5038>,
			<6522 5973 5486 5138 5056 5038>,
			<6455 5960 5489 5140 5055 5038>,
			<6392 5944 5489 5141 5056 5039>,
			<6338 5928 5487 5142 5056 5039>,
			<6296 5909 5484 5143 5057 5040>,
			<6269 5890 5477 5143 5058 5041>,
			<6247 5869 5466 5144 5059 5042>,
			<6216 5845 5460 5145 5060 5043>,
			<6166 5813 5456 5146 5061 5045>,
			<6135 5794 5453 5147 5063 5046>,
			<6139 5802 5448 5148 5065 5048>,
			<6148 5820 5442 5150 5068 5050>,
			<6141 5821 5441 5152 5071 5052>,
			<6054 5778 5441 5156 5073 5054>,
			<5976 5730 5442 5161 5076 5057>,
			<5968 5705 5431 5167 5081 5061>,
			<5965 5686 5406 5172 5086 5064>,
			<5961 5671 5385 5174 5089 5068>,
			<5953 5658 5367 5166 5092 5073>,
			<5945 5647 5351 5154 5093 5076>,
			<5938 5637 5339 5140 5083 5066>,
			<5932 5628 5330 5122 5060 5045>,
			<5930 5619 5324 5115 5051 5037>,
			<5933 5610 5321 5114 5050 5036>,
			<5939 5604 5319 5114 5049 5036>,
			<5948 5607 5315 5114 5050 5036>,
			<5961 5619 5312 5116 5052 5038>,
			<5977 5633 5311 5118 5055 5040>,
			<5994 5648 5316 5121 5059 5043>,
			<6014 5666 5325 5124 5062 5047>,
			<6035 5686 5336 5126 5066 5051>,
			<6056 5710 5353 5128 5070 5055>,
			<6079 5736 5371 5130 5071 5056>,
			<6106 5767 5392 5132 5070 5055>,
			<6136 5800 5416 5134 5067 5052>,
			<6165 5832 5444 5134 5063 5048>,
			<6195 5863 5476 5134 5056 5041>,
			<6226 5895 5509 5135 5054 5039>,
			<6256 5928 5545 5138 5055 5040>,
			<6287 5961 5582 5147 5058 5042>,
			<6319 5989 5624 5155 5059 5043>,
			<6353 6014 5669 5166 5059 5043>,
			<6397 6042 5710 5177 5059 5041>,
			<6452 6076 5756 5189 5057 5039>,
			<6497 6114 5797 5209 5065 5047>,
			<6472 6112 5796 5204 5069 5052>,
			<6511 6144 5837 5210 5077 5062>,
			<6567 6186 5885 5228 5088 5070>,
			<6618 6224 5930 5242 5084 5063>,
			<6676 6257 5966 5244 5071 5048>,
			<6754 6304 6025 5261 5073 5050>,
			<6862 6382 6110 5295 5084 5056>,
			<7268 6492 6210 5351 5104 5074>,
			<7268 6492 6210 5351 5104 5074>,
			<7268 6492 6210 5351 5104 5074>;
	};

};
